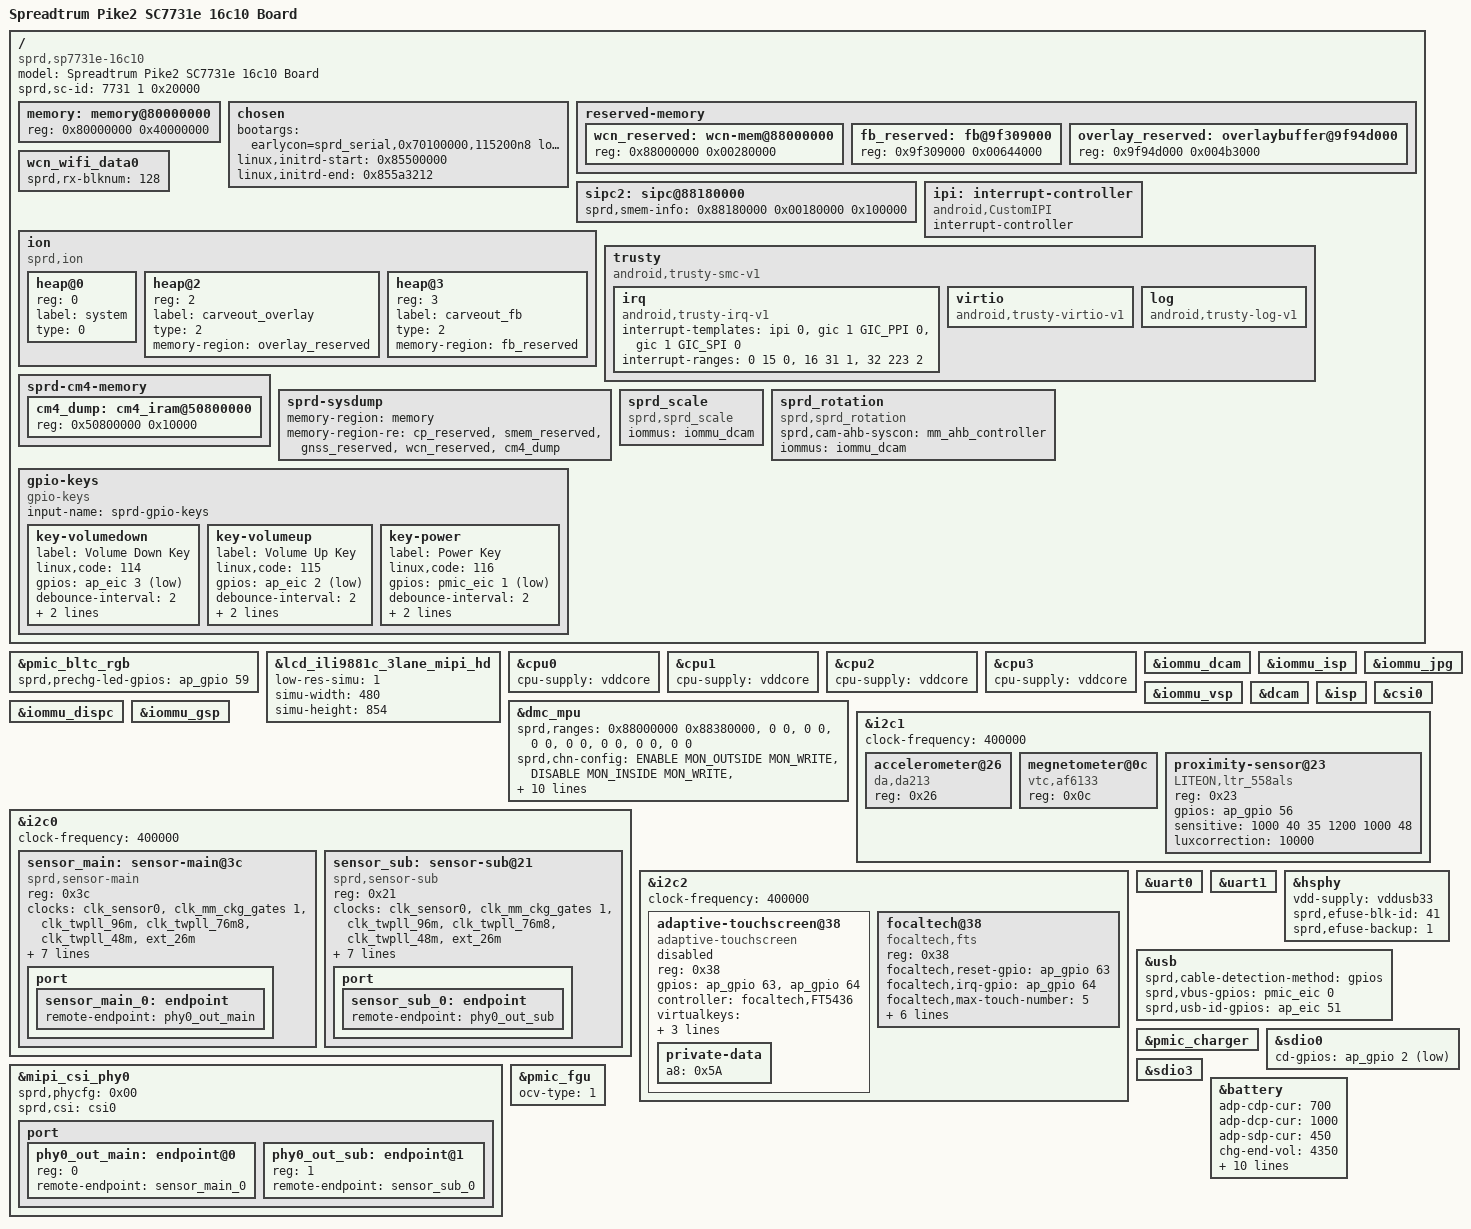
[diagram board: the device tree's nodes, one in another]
/*
 * Spreadtrum Pike2 SP7731e DTS file
 *
 * Copyright (C) 2016-2017, Spreadtrum Communications Inc.
 *
 * This file is licensed under a dual GPLv2 or X11 license.
 */

#include "sc7731e.dtsi"
#include "sp7731e-common.dtsi"

/ {
	model = "Spreadtrum Pike2 SC7731e 16c10 Board";

	compatible = "sprd,sp7731e-16c10", "sprd,sc7731e";

	sprd,sc-id = <7731 1 0x20000>;

	memory: memory@80000000 {
		device_type = "memory";
		reg = <0x80000000 0x40000000>;
	};

	chosen {
		bootargs = "earlycon=sprd_serial,0x70100000,115200n8 loglevel=1 console=ttyS1,115200n8 init=/init root=/dev/ram0 rw androidboot.hardware=sp7731e_16c10";
		linux,initrd-start = <0x85500000>;
		linux,initrd-end = <0x855a3212>;
	};

	reserved-memory {
		#address-cells = <1>;
		#size-cells = <1>;
		ranges;

		/* must be 32M aligned */
		wcn_reserved: wcn-mem@88000000 {
		      reg = <0x88000000 0x00280000>;
		};

		fb_reserved: fb@9f309000{
			reg = <0x9f309000 0x00644000>;
		};

		overlay_reserved: overlaybuffer@9f94d000{
			reg = <0x9f94d000 0x004b3000>;
		};
	};

	sipc2: sipc@88180000 {
		/* <ap-addr dst-maped-addr size> */
		sprd,smem-info = <0x88180000 0x00180000 0x100000>;
	};

	wcn_wifi_data0 {
		sprd,rx-blknum = <128>;
	};

	ion {
		compatible = "sprd,ion";
		#address-cells = <1>;
		#size-cells = <0>;

		heap@0 {
			reg = <0>;
			label = "system";
			type = <0>;
		};

		heap@2 {
			reg = <2>;
			label = "carveout_overlay";
			type = <2>;
			memory-region = <&overlay_reserved>;
		};

		heap@3 {
			reg = <3>;
			label = "carveout_fb";
			type = <2>;
			memory-region = <&fb_reserved>;
		};
	};

	ipi: interrupt-controller {
		compatible = "android,CustomIPI";
		#interrupt-cells = <1>;
		interrupt-controller;
	};

	trusty {
		compatible = "android,trusty-smc-v1";

		irq {
			compatible = "android,trusty-irq-v1";
			interrupt-templates = <&ipi 0>,
						<&gic 1 GIC_PPI 0>,
						<&gic 1 GIC_SPI 0>;
			interrupt-ranges = < 0  15 0>,
						<16  31 1>,
						<32 223 2>;
		};

		virtio {
			compatible = "android,trusty-virtio-v1";
		};

		log {
			compatible = "android,trusty-log-v1";
		};
	};

	sprd-cm4-memory {
		#address-cells = <1>;
		#size-cells = <1>;
		ranges;

		cm4_dump: cm4_iram@50800000 {
			reg = <0x50800000 0x10000>;
		};
	};

	sprd-sysdump {
		memory-region = <&memory>;
		memory-region-re = <&cp_reserved>, <&smem_reserved>,
				<&gnss_reserved>, <&wcn_reserved>,
				<&cm4_dump>;
	};

	sprd_scale {
		compatible = "sprd,sprd_scale";
		iommus = <&iommu_dcam>;
		status = "okay";
	};

	sprd_rotation {
		compatible = "sprd,sprd_rotation";
		sprd,cam-ahb-syscon = <&mm_ahb_controller>;
		iommus = <&iommu_dcam>;
		status = "okay";
	};

	gpio-keys {
		compatible = "gpio-keys";
		input-name = "sprd-gpio-keys";
		status = "okay";

		key-volumedown {
			label = "Volume Down Key";
			linux,code = <114>;
			gpios = <&ap_eic 3 1>;
			debounce-interval = <2>;
			gpio-key,wakeup;
			gpio-key,level-trigger;
		};

		key-volumeup {
			label = "Volume Up Key";
			linux,code = <115>;
			gpios = <&ap_eic 2 1>;
			debounce-interval = <2>;
			gpio-key,wakeup;
			gpio-key,level-trigger;
		};

		key-power {
			label = "Power Key";
			linux,code = <116>;
			gpios = <&pmic_eic 1 1>;
			debounce-interval = <2>;
			gpio-key,wakeup;
			gpio-key,level-trigger;
		};
	};

};

&pmic_bltc_rgb {
	status = "okay";
	sprd,prechg-led-gpios = <&ap_gpio 59 0>;
};

&lcd_ili9881c_3lane_mipi_hd {
	low-res-simu = <1>;
	simu-width = <480>;
	simu-height = <854>;
};

&cpu0 {
	cpu-supply = <&vddcore>;
};
&cpu1 {
	cpu-supply = <&vddcore>;
};
&cpu2 {
	cpu-supply = <&vddcore>;
};
&cpu3 {
	cpu-supply = <&vddcore>;
};

&dmc_mpu {
	status = "okay";
	sprd,ranges = <0x88000000 0x88380000>,
		      <0 0>,
		      <0 0>,
		      <0 0>,
		      <0 0>,
		      <0 0>,
		      <0 0>,
		      <0 0>;
	sprd,chn-config =
			<ENABLE MON_OUTSIDE MON_WRITE>,
			<DISABLE MON_INSIDE MON_WRITE>,
			<DISABLE MON_INSIDE MON_WRITE>,
			<DISABLE MON_INSIDE MON_WRITE>,
			<DISABLE MON_INSIDE MON_WRITE>,
			<DISABLE MON_INSIDE MON_WRITE>,
			<DISABLE MON_INSIDE MON_WRITE>,
			<DISABLE MON_INSIDE MON_WRITE>;
	sprd,id-config =
			<USERID 0xc0 0xc0>, <MPUID 0 0>,
			<MPUID 0 0>, <MPUID 0 0>,
			<MPUID 0 0>, <MPUID 0 0>,
			<MPUID 0 0>, <MPUID 0 0>;
	sprd,panic;
};

&iommu_dcam {
	status = "okay";
};

&iommu_isp {
	status = "okay";
};

&iommu_jpg {
	status = "okay";
};

&iommu_vsp {
	status = "okay";
};

&dcam {
	status = "okay";
};

&isp {
	status = "okay";
};

&csi0 {
	status = "okay";
};

&iommu_dispc {
	status = "okay";
};

&iommu_gsp {
	status = "okay";
};

&i2c0 {
	status = "okay";
	clock-frequency = <400000>;

	sensor_main: sensor-main@3c {
		compatible = "sprd,sensor-main";
		reg = <0x3c>;
		clock-names = "clk_src", "sensor_eb",
			"clk_96m", "clk_76m8",
			"clk_48m", "clk_26m";
		clocks  = <&clk_sensor0>,
			<&clk_mm_ckg_gates 1>,
			<&clk_twpll_96m>,
			<&clk_twpll_76m8>,
			<&clk_twpll_48m>,
			<&ext_26m>;
		vddio-supply = <&vddcamio>;
		vddcama-supply = <&vddcama>;
		vddcamd-supply = <&vddcamd>;
		vddcammot-supply = <&vddcammot>;
		reset-gpios = <&ap_gpio 37 0>;
		power-down-gpios = <&ap_gpio 38 0>;
		host = "dcam0";
		port {
			sensor_main_0: endpoint {
				remote-endpoint = <&phy0_out_main>;
			};
		};
	};

	sensor_sub: sensor-sub@21 {
		compatible = "sprd,sensor-sub";
		reg = <0x21>;
		clock-names = "clk_src","sensor_eb",
			"clk_96m", "clk_76m8",
			"clk_48m", "clk_26m";
		clocks = <&clk_sensor0>,
			<&clk_mm_ckg_gates 1>,
			<&clk_twpll_96m>,
			<&clk_twpll_76m8>,
			<&clk_twpll_48m>,
			<&ext_26m>;
		vddio-supply = <&vddcamio>;
		vddcama-supply = <&vddcama>;
		vddcamd-supply = <&vddcamd>;
		vddcammot-supply = <&vddcammot>;
		reset-gpios = <&ap_gpio 46 0>;
		power-down-gpios = <&ap_gpio 39 0>;
		host = "dcam0";
		port {
			sensor_sub_0: endpoint {
				remote-endpoint = <&phy0_out_sub>;
			};
		};
	};
};

&i2c1 {
	status = "okay";
	clock-frequency = <400000>;

	accelerometer@26 {
		compatible = "da,da213";
		reg = <0x26>;
	};

	megnetometer@0c {
		compatible = "vtc,af6133";
		reg = <0x0c>;
	};

	proximity-sensor@23 {
		compatible = "LITEON,ltr_558als";
		reg = <0x23>;
		gpios = <&ap_gpio 56 0>;
		/*
		 *low sensitve(def):1500,250,220,1800,1600,1;
		 *have no sensitve=<> as def.
		 * High sensitve:1000,40,35,1200,1000,48
		 */
		sensitive = <1000 40 35
					1200 1000 48>;
		luxcorrection = <10000>;
	};
};

&i2c2 {
	status = "okay";
	clock-frequency = <400000>;
	adaptive-touchscreen@38 {
		status = "disable";
		compatible = "adaptive-touchscreen";
		reg = <0x38>;
		gpios = <&ap_gpio 63 0
			&ap_gpio 64 0>;
		controller = "focaltech,FT5436";
		virtualkeys = <580 60 1320 60 45
			172 360 1320 60 45
			158 600 1320 60 45>;
		surface-width = <480>;
		surface-height = <854>;
		private-data {
			a8 = /bits/ 8 <0x5A>;
		};
	};

	focaltech@38{
		compatible = "focaltech,fts";
		reg = <0x38>;

		focaltech,reset-gpio = <&ap_gpio 63 0>;
		focaltech,irq-gpio = <&ap_gpio 64 0>;
		focaltech,max-touch-number = <5>;
		focaltech,display-coords =  <0 0 480 800>;

		focaltech,have-key;
		focaltech,key-number = <3>;
		focaltech,keys = <158 172 580>;
		focaltech,key-y-coord = <900>;
		focaltech,key-x-coords = <80 240 400>;
	};
};

&mipi_csi_phy0 {
	status = "okay";
	sprd,phycfg = <0x00>;
	sprd,csi = <&csi0>;
	port {
		#address-cells = <1>;
		#size-cells = <0>;
		phy0_out_main: endpoint@0 {
			reg = <0>;
			remote-endpoint = <&sensor_main_0>;
		};
		phy0_out_sub: endpoint@1 {
			reg = <1>;
			remote-endpoint = <&sensor_sub_0>;
		};
	};
};

&uart0 {
	status = "okay";
};

&uart1 {
	status = "okay";
};

&hsphy {
	vdd-supply = <&vddusb33>;
	sprd,efuse-blk-id = <41>;
	sprd,efuse-backup = <1>;
};

&usb {
	sprd,cable-detection-method = "gpios";
	sprd,vbus-gpios = <&pmic_eic 0 0>;
	sprd,usb-id-gpios = <&ap_eic 51 0>;
};

&pmic_charger {
	status = "okay";
};

&sdio0 {
	cd-gpios = <&ap_gpio 2 1>;
};

&sdio3 {
	/delete-property/ mmc-hs400-enhanced-strobe;
	/delete-property/ mmc-hs400-1_8v;
	/delete-property/ mmc-hs200-1_8v;
	/delete-property/ mmc-ddr-1_8v;
};

&battery {
	adp-cdp-cur = <700>;
	adp-dcp-cur = <1000>;
	adp-sdp-cur = <450>;
	chg-end-vol = <4350>;
	chg-end-vol-check = <4330>;
	chg-bat-safety-vol = <4430>;
	rechg-vol = <4270>;
	rsense-real = <200>;
	rint = <320>;
	cnom = <2780>;
	ocv-tab-vol = <4340 4243 4185 4132 4083 4037 3996
			3959 3921 3876 3842 3818 3800 3786
			3776 3768 3753 3731 3696 3663 3400>;
	ocv-tab-cap = <100  95   90   85   80   75   70
			65   60   55   50   45   40   35
			30   25   20   15   10   5    0>;
};

&pmic_charger {
	status = "okay";
};

&pmic_fgu {
	ocv-type = <1>;
};
